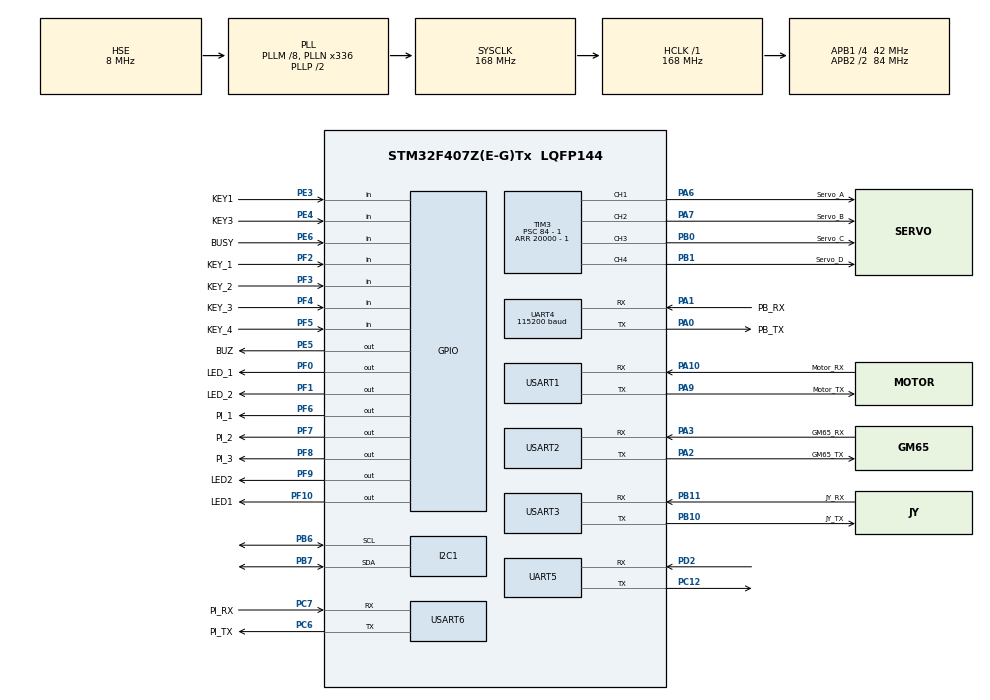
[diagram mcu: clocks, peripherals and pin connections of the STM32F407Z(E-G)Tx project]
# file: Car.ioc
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Dma.Request0=USART3_RX
Dma.USART3_RX.0.Direction=DMA_PERIPH_TO_MEMORY
Dma.USART3_RX.0.FIFOMode=DMA_FIFOMODE_DISABLE
Dma.USART3_RX.0.Instance=DMA1_Stream1
Dma.USART3_RX.0.MemDataAlignment=DMA_MDATAALIGN_BYTE
Dma.USART3_RX.0.MemInc=DMA_MINC_ENABLE
Dma.USART3_RX.0.Mode=DMA_NORMAL
Dma.USART3_RX.0.PeriphDataAlignment=DMA_PDATAALIGN_BYTE
Dma.USART3_RX.0.PeriphInc=DMA_PINC_DISABLE
Dma.USART3_RX.0.Priority=DMA_PRIORITY_LOW
I2C1.I2C_Mode=I2C_Fast
Mcu.Family=STM32F4
Mcu.Name=STM32F407Z(E-G)Tx
Mcu.Package=LQFP144
NVIC.DMA1_Stream1_IRQn=true\:0\:0\:false\:false\:true\:false\:true\:true
NVIC.PriorityGroup=NVIC_PRIORITYGROUP_4
NVIC.TIM6_DAC_IRQn=true\:0\:0\:false\:false\:true\:true\:true\:true
NVIC.UART4_IRQn=true\:0\:0\:true\:false\:true\:true\:true\:true
NVIC.USART1_IRQn=true\:1\:0\:true\:false\:true\:true\:true\:true
NVIC.USART2_IRQn=true\:2\:0\:true\:false\:true\:true\:true\:true
NVIC.USART3_IRQn=true\:3\:0\:true\:false\:true\:true\:true\:true
NVIC.USART6_IRQn=true\:2\:0\:true\:false\:true\:true\:true\:true
PA0-WKUP.GPIO_Label=PB_TX
PA0-WKUP.Mode=Asynchronous
PA0-WKUP.Signal=UART4_TX
PA1.GPIO_Label=PB_RX
PA1.Mode=Asynchronous
PA1.Signal=UART4_RX
PA10.GPIO_Label=Motor_RX
PA10.Mode=Asynchronous
PA10.Signal=USART1_RX
PA2.GPIO_Label=GM65_TX
PA2.GPIO_Speed=GPIO_SPEED_FREQ_MEDIUM
PA2.Mode=Asynchronous
PA2.Signal=USART2_TX
PA3.GPIO_Label=GM65_RX
PA3.GPIO_Speed=GPIO_SPEED_FREQ_MEDIUM
PA3.Mode=Asynchronous
PA3.Signal=USART2_RX
PA6.GPIO_Label=Servo_A
PA6.Signal=S_TIM3_CH1
PA7.GPIO_Label=Servo_B
PA7.Signal=S_TIM3_CH2
PA9.GPIO_Label=Motor_TX
PA9.Mode=Asynchronous
PA9.Signal=USART1_TX
PB0.GPIO_Label=Servo_C
PB0.Signal=S_TIM3_CH3
PB1.GPIO_Label=Servo_D
PB1.Signal=S_TIM3_CH4
PB10.GPIO_Label=JY_TX
PB10.Mode=Asynchronous
PB10.Signal=USART3_TX
PB11.GPIO_Label=JY_RX
PB11.Mode=Asynchronous
PB11.Signal=USART3_RX
PB6.Mode=I2C
PB6.Signal=I2C1_SCL
PB7.Mode=I2C
PB7.Signal=I2C1_SDA
PC12.Mode=Asynchronous
PC12.Signal=UART5_TX
PC6.GPIO_Label=PI_TX
PC6.Mode=Asynchronous
PC6.Signal=USART6_TX
PC7.GPIO_Label=PI_RX
PC7.Mode=Asynchronous
PC7.Signal=USART6_RX
PD2.Mode=Asynchronous
PD2.Signal=UART5_RX
PE3.GPIO_Label=KEY1
PE3.GPIO_PuPd=GPIO_PULLUP
PE3.Signal=GPIO_Input
PE4.GPIO_Label=KEY3
PE4.GPIO_PuPd=GPIO_PULLUP
PE4.Signal=GPIO_Input
PE5.GPIO_Label=BUZ
PE5.Signal=GPIO_Output
PE6.GPIO_Label=BUSY
PE6.Signal=GPIO_Input
PF0.GPIO_Label=LED_1
PF0.GPIO_PuPd=GPIO_NOPULL
PF0.Signal=GPIO_Output
PF1.GPIO_Label=LED_2
PF1.GPIO_PuPd=GPIO_NOPULL
PF1.Signal=GPIO_Output
PF10.GPIO_Label=LED1
PF10.PinState=GPIO_PIN_SET
PF10.Signal=GPIO_Output
PF2.GPIO_Label=KEY_1
PF2.GPIO_PuPd=GPIO_PULLUP
PF2.Signal=GPIO_Input
PF3.GPIO_Label=KEY_2
PF3.GPIO_PuPd=GPIO_PULLUP
PF3.Signal=GPIO_Input
PF4.GPIO_Label=KEY_3
PF4.GPIO_PuPd=GPIO_PULLUP
PF4.Signal=GPIO_Input
PF5.GPIO_Label=KEY_4
PF5.GPIO_PuPd=GPIO_PULLUP
PF5.Signal=GPIO_Input
PF6.GPIO_Label=PI_1
PF6.Signal=GPIO_Output
PF7.GPIO_Label=PI_2
PF7.Signal=GPIO_Output
PF8.GPIO_Label=PI_3
PF8.Signal=GPIO_Output
PF9.GPIO_Label=LED2
PF9.PinState=GPIO_PIN_SET
PF9.Signal=GPIO_Output
PH0-OSC_IN.Mode=HSE-External-Oscillator
PH0-OSC_IN.Signal=RCC_OSC_IN
PH1-OSC_OUT.Mode=HSE-External-Oscillator
PH1-OSC_OUT.Signal=RCC_OSC_OUT
ProjectManager.HeapSize=0x200
ProjectManager.StackSize=0x400
ProjectManager.TargetToolchain=STM32CubeIDE
RCC.48MHZClocksFreq_Value=84000000
RCC.AHBFreq_Value=168000000
RCC.APB1CLKDivider=RCC_HCLK_DIV4
RCC.APB1Freq_Value=42000000
RCC.APB1TimFreq_Value=84000000
RCC.APB2CLKDivider=RCC_HCLK_DIV2
RCC.APB2Freq_Value=84000000
RCC.APB2TimFreq_Value=168000000
RCC.CortexFreq_Value=168000000
RCC.HCLKFreq_Value=168000000
RCC.HSE_VALUE=8000000
RCC.HSI_VALUE=16000000
RCC.LSE_VALUE=32768
RCC.PLLM=8
RCC.PLLN=336
RCC.PLLSourceVirtual=RCC_PLLSOURCE_HSE
RCC.SYSCLKFreq_VALUE=168000000
RCC.SYSCLKSource=RCC_SYSCLKSOURCE_PLLCLK
RCC.VCOOutputFreq_Value=336000000
SH.S_TIM3_CH1.0=TIM3_CH1,PWM Generation1 CH1
SH.S_TIM3_CH2.0=TIM3_CH2,PWM Generation2 CH2
SH.S_TIM3_CH3.0=TIM3_CH3,PWM Generation3 CH3
SH.S_TIM3_CH4.0=TIM3_CH4,PWM Generation4 CH4
TIM3.AutoReloadPreload=TIM_AUTORELOAD_PRELOAD_ENABLE
TIM3.Channel-PWM\ Generation1\ CH1=TIM_CHANNEL_1
TIM3.Channel-PWM\ Generation2\ CH2=TIM_CHANNEL_2
TIM3.Channel-PWM\ Generation3\ CH3=TIM_CHANNEL_3
TIM3.Channel-PWM\ Generation4\ CH4=TIM_CHANNEL_4
TIM3.Period=20000 - 1
TIM3.Prescaler=84 - 1
TIM6.AutoReloadPreload=TIM_AUTORELOAD_PRELOAD_ENABLE
TIM6.Period=100 - 1
TIM6.Prescaler=8400 - 1
TIM7.AutoReloadPreload=TIM_AUTORELOAD_PRELOAD_ENABLE
TIM7.Period=100 - 1
TIM7.Prescaler=8400 - 1
UART4.BaudRate=115200
UART4.VirtualMode=Asynchronous
UART5.VirtualMode=Asynchronous
USART1.VirtualMode=VM_ASYNC
USART2.VirtualMode=VM_ASYNC
USART3.VirtualMode=VM_ASYNC
USART6.VirtualMode=VM_ASYNC
VP_TIM3_VS_ClockSourceINT.Mode=Internal
VP_TIM6_VS_ClockSourceINT.Mode=Enable_Timer
VP_TIM7_VS_ClockSourceINT.Mode=Enable_Timer
board=custom

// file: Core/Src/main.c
/* USER CODE BEGIN Header */
/**
  ******************************************************************************
  * @file           : main.c
  * @brief          : Main program body
  ******************************************************************************
  * @attention
  *
  * Copyright (c) 2024 STMicroelectronics.
  * All rights reserved.
  *
  * This software is licensed under terms that can be found in the LICENSE file
  * in the root directory of this software component.
  * If no LICENSE file comes with this software, it is provided AS-IS.
  *
  ******************************************************************************
  */
/* USER CODE END Header */
#include "main.h"
#include "dma.h"
#include "i2c.h"
#include "tim.h"
#include "usart.h"
#include "gpio.h"

/* USER CODE BEGIN Includes */
#include "../../Bsp/Bsp.h"
/* USER CODE END Includes */

void SystemClock_Config(void);

int main(void)
{

  /* USER CODE BEGIN 1 */
    RetargetInit(&huart5);
  /* USER CODE END 1 */

  /* MCU Configuration--------------------------------------------------------*/

  /* Reset of all peripherals, Initializes the Flash interface and the Systick. */
  HAL_Init();

  /* Configure the system clock */
  SystemClock_Config();

  /* Initialize all configured peripherals */
  MX_GPIO_Init();
  MX_DMA_Init();
  MX_UART5_Init();
  MX_USART1_UART_Init();
  MX_TIM3_Init();
  MX_TIM6_Init();
  MX_TIM7_Init();
  MX_USART3_UART_Init();
  MX_UART4_Init();
  MX_USART2_UART_Init();
  MX_USART6_UART_Init();
  MX_I2C1_Init();
  /* USER CODE BEGIN 2 */
    Bsp_Init();

    printf("Start OK!\r\n");
    uint8_t time = 0;
    uint8_t flag = 0;

//Task_Num_0

    printf("Tar send!\r\n");

    static uint8_t flag_huagui = 0;

  /* USER CODE END 2 */

  /* Infinite loop */
    while (1) {

    /* USER CODE BEGIN 3 */

        //printf("Yaw : %f\n",Yaw);

//        printf(" x : %.2f", JY901_data.angle.angle[0]);
//        printf(" y : %.2f", JY901_data.angle.angle[1]);
//        printf(" z : %.2f \n", JY901_data.angle.angle[2]);

//        printf(" SP_x : %.2f", JY901_data.acc.a[0]);
//        printf(" SP_y : %.2f", JY901_data.acc.a[1]);
//        printf(" SP_z : %.2f \r\n", JY901_data.acc.a[2]);

//        if (HuaGui_Init_State == 0) {
//            static uint8_t num = 0;
//            if (num == 0 && Running_Flag == 0) {
//                //滑轨向外
//                printf("HuaGui OUT!\n");
//                Task_Num_0 = 4;
//                Task_Num_1 = 1;
//                num = 1;
//            }
//            else if (num == 1 && Running_Flag == 0) {
//                //出启动区
//                Task_Num_0 = 1;
//                Task_Num_1 = -21;
//                Task_Num_2 = 65;
//                num = 2;
//            }
//            else if (num == 1 && Running_Flag == 0) {
//                printf("Jia wukuai!\n");
//                Task_Num_0 = 5;
//                Task_Num_1 = 1;
//                Task_Num_2 = 0;
//                num = 2;
//            }
//            else if (num == 2 && Running_Flag == 0) {
//                //行驶到物料
//                Task_Num_0 = 6;
//                Task_Num_1 = 1;
//                Task_Num_2 = 0;
//                num = 3;
//            }
//            else if (num == 3 && Running_Flag == 0) {
//                //行驶到物料
//                Task_Num_0 = 1;
//                Task_Num_1 = 10;
//                Task_Num_2 = 83;
//                num = 4;
//            }
//            else if (num == 4 && Running_Flag == 0) {
//                //车身角度回正
//                Task_Num_0 = 7;
//                num = 5;
//            } else if (num == 5 && Running_Flag == 0) {
//                //到拐角
//                Task_Num_0 = 1;
//                Task_Num_1 = -5;
//                Task_Num_2 = 42;
//                num = 6;
//            } else if (num == 6 && Running_Flag == 0) {
//                Task_Num_0 = 2;
//                Task_Num_1 = 90;
//                num = 7;
//            } else if (num == 7 && Running_Flag == 0) {
//                Task_Num_0 = 1;
//                Task_Num_1 = 10;
//                Task_Num_2 = 75;
//                num = 8;
//            } else if (num == 8 && Running_Flag == 0) {
//                Task_Num_0 = 7;
//                num = 9;
//            }
//        }

        Key_Proc();
        Process_OP_Data();
        PI_Data_Receive_Proc();
        HuaGui_Init_Proc();
        Control_Proc();
        process_kalman_filter();

//        if (HuaGui_Init_State == 0) {
////            printf("HuaGui Task 0!\n");
////            JiaZhua_Turn(JiaZhua_Close);
////            HuaGui_Turn(HuaGui_OUT);
////            ZaiWu_Turn(ZaiWu_Right);
////            flag_huagui = 1;
//
//
//
//            HuaGui_Init_State = 20;
//        } else if (HuaGui_Init_State == 10 && Running_Flag == 0) {
//
//            PI_Data0 = 10;
//            PI_Data1 = 0;
//            PI_Data2 = 0;
//
//            HuaGui_Init_State = 20;
//        } else if (HuaGui_Init_State == 20 && Running_Flag == 0) {
//
//            PI_Data0 = 1;
//            PI_Data1 = -30;
//            PI_Data2 = 100;
//
//            HuaGui_Init_State = 30;
//        } else if (HuaGui_Init_State == 30 && Running_Flag == 0) {
//            PI_Data0 = 1;
//            PI_Data1 = 40;
//            PI_Data2 = 50;
//
//            HuaGui_Init_State = 40;
//        } else if (HuaGui_Init_State == 40 && Running_Flag == 0){
//            PI_Data0 = 2;
//            PI_Data1 = 90;
//            PI_Data2 = 0;
//
//            HuaGui_Init_State = 50;
//        }else if (HuaGui_Init_State == 50 && Running_Flag == 0){
//            PI_Data0 = 7;
//            PI_Data1 = 0;
//            PI_Data2 = 0;
//            HuaGui_Init_State = 60;
//        }else if (HuaGui_Init_State == 60 && Running_Flag == 0){
//            PI_Data0 = 2;
//            PI_Data1 = 90;
//            PI_Data2 = 0;
//            HuaGui_Init_State = 70;
//
//        }else if (HuaGui_Init_State == 70 && Running_Flag == 0) {
//            PI_Data0 = 7;
//            PI_Data1 = 0;
//            PI_Data2 = 0;
//            HuaGui_Init_State = 100;
//        }

//        Delay_ms(100);

    }
  /* USER CODE END 3 */
}

void SystemClock_Config(void)
{
  RCC_OscInitTypeDef RCC_OscInitStruct = {0};
  RCC_ClkInitTypeDef RCC_ClkInitStruct = {0};

  /** Configure the main internal regulator output voltage
  */
  __HAL_RCC_PWR_CLK_ENABLE();
  __HAL_PWR_VOLTAGESCALING_CONFIG(PWR_REGULATOR_VOLTAGE_SCALE1);

  /** Initializes the RCC Oscillators according to the specified parameters
  * in the RCC_OscInitTypeDef structure.
  */
  RCC_OscInitStruct.OscillatorType = RCC_OSCILLATORTYPE_HSE;
  RCC_OscInitStruct.HSEState = RCC_HSE_ON;
  RCC_OscInitStruct.PLL.PLLState = RCC_PLL_ON;
  RCC_OscInitStruct.PLL.PLLSource = RCC_PLLSOURCE_HSE;
  RCC_OscInitStruct.PLL.PLLM = 8;
  RCC_OscInitStruct.PLL.PLLN = 336;
  RCC_OscInitStruct.PLL.PLLP = RCC_PLLP_DIV2;
  RCC_OscInitStruct.PLL.PLLQ = 4;
  if (HAL_RCC_OscConfig(&RCC_OscInitStruct) != HAL_OK)
  {
    Error_Handler();
  }

  /** Initializes the CPU, AHB and APB buses clocks
  */
  RCC_ClkInitStruct.ClockType = RCC_CLOCKTYPE_HCLK|RCC_CLOCKTYPE_SYSCLK
                              |RCC_CLOCKTYPE_PCLK1|RCC_CLOCKTYPE_PCLK2;
  RCC_ClkInitStruct.SYSCLKSource = RCC_SYSCLKSOURCE_PLLCLK;
  RCC_ClkInitStruct.AHBCLKDivider = RCC_SYSCLK_DIV1;
  RCC_ClkInitStruct.APB1CLKDivider = RCC_HCLK_DIV4;
  RCC_ClkInitStruct.APB2CLKDivider = RCC_HCLK_DIV2;

  if (HAL_RCC_ClockConfig(&RCC_ClkInitStruct, FLASH_LATENCY_5) != HAL_OK)
  {
    Error_Handler();
  }
}

void Error_Handler(void)
{
    __disable_irq();
    while (1) {
    }
}
